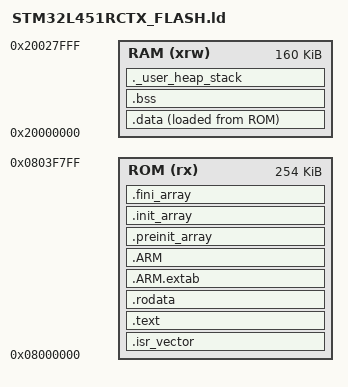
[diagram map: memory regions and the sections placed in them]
/*
 * Linker script for STM32L451RCTx: 256 KB flash, 160 KB RAM
 * (SRAM1 128 KB + SRAM2 32 KB, contiguous at 0x20000000 on STM32L45x).
 * Adapted from ST's CubeIDE template for the STM32L452RE.
 */
ENTRY(Reset_Handler)

_estack = ORIGIN(RAM) + LENGTH(RAM);
_Min_Heap_Size  = 0x400;
_Min_Stack_Size = 0x1000;

MEMORY
{
  RAM (xrw) : ORIGIN = 0x20000000, LENGTH = 160K
  /* Last 2 KB page (0x0803F800) is reserved for user settings (stage 2, PLAN.md) */
  ROM (rx)  : ORIGIN = 0x08000000, LENGTH = 254K
}

SECTIONS
{
  .isr_vector :
  {
    . = ALIGN(4);
    KEEP(*(.isr_vector))
    . = ALIGN(4);
  } >ROM

  .text :
  {
    . = ALIGN(4);
    *(.text)
    *(.text*)
    *(.glue_7)
    *(.glue_7t)
    *(.eh_frame)
    KEEP (*(.init))
    KEEP (*(.fini))
    . = ALIGN(4);
    _etext = .;
  } >ROM

  .rodata :
  {
    . = ALIGN(4);
    *(.rodata)
    *(.rodata*)
    . = ALIGN(4);
  } >ROM

  .ARM.extab (READONLY) : { *(.ARM.extab* .gnu.linkonce.armextab.*) } >ROM
  .ARM (READONLY) :
  {
    __exidx_start = .;
    *(.ARM.exidx*)
    __exidx_end = .;
  } >ROM

  .preinit_array (READONLY) :
  {
    PROVIDE_HIDDEN (__preinit_array_start = .);
    KEEP (*(.preinit_array*))
    PROVIDE_HIDDEN (__preinit_array_end = .);
  } >ROM
  .init_array (READONLY) :
  {
    PROVIDE_HIDDEN (__init_array_start = .);
    KEEP (*(SORT(.init_array.*)))
    KEEP (*(.init_array*))
    PROVIDE_HIDDEN (__init_array_end = .);
  } >ROM
  .fini_array (READONLY) :
  {
    PROVIDE_HIDDEN (__fini_array_start = .);
    KEEP (*(SORT(.fini_array.*)))
    KEEP (*(.fini_array*))
    PROVIDE_HIDDEN (__fini_array_end = .);
  } >ROM

  _sidata = LOADADDR(.data);

  .data :
  {
    . = ALIGN(4);
    _sdata = .;
    *(.data)
    *(.data*)
    *(.RamFunc)
    *(.RamFunc*)
    . = ALIGN(4);
    _edata = .;
  } >RAM AT> ROM

  .bss :
  {
    . = ALIGN(4);
    _sbss = .;
    __bss_start__ = _sbss;
    *(.bss)
    *(.bss*)
    *(COMMON)
    . = ALIGN(4);
    _ebss = .;
    __bss_end__ = _ebss;
  } >RAM

  ._user_heap_stack :
  {
    . = ALIGN(8);
    PROVIDE ( end = . );
    PROVIDE ( _end = . );
    . = . + _Min_Heap_Size;
    . = . + _Min_Stack_Size;
    . = ALIGN(8);
  } >RAM

  /DISCARD/ :
  {
    libc.a ( * )
    libm.a ( * )
    libgcc.a ( * )
  }

  .ARM.attributes 0 : { *(.ARM.attributes) }
}
